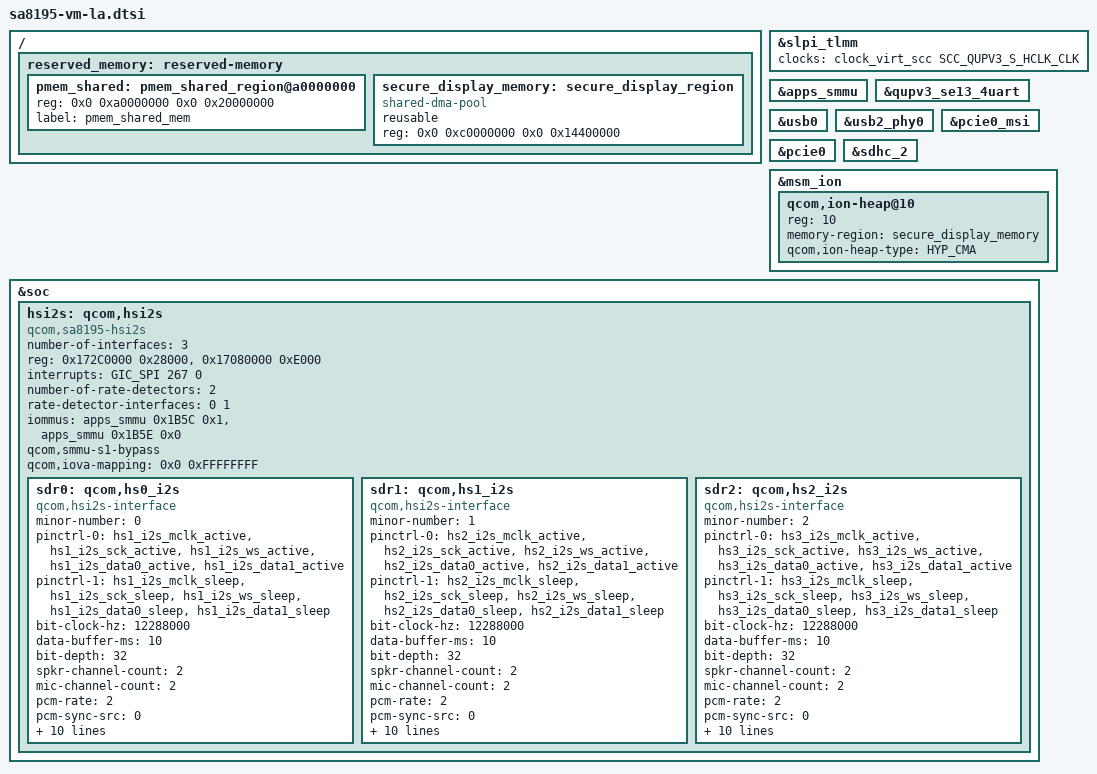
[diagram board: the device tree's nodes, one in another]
/* Copyright (c) 2019-2020, The Linux Foundation. All rights reserved.
 *
 * This program is free software; you can redistribute it and/or modify
 * it under the terms of the GNU General Public License version 2 and
 * only version 2 as published by the Free Software Foundation.
 *
 * This program is distributed in the hope that it will be useful,
 * but WITHOUT ANY WARRANTY; without even the implied warranty of
 * MERCHANTABILITY or FITNESS FOR A PARTICULAR PURPOSE.  See the
 * GNU General Public License for more details.
 */

/ {
	reserved_memory: reserved-memory {

		pmem_shared: pmem_shared_region@a0000000 {
			reg = <0x0 0xa0000000 0x0 0x20000000>;
			label = "pmem_shared_mem";
		};

		secure_display_memory: secure_display_region {
			compatible = "shared-dma-pool";
			reusable;
			reg = <0x0 0xc0000000 0x0 0x14400000>;
		};
	};

};

&slpi_tlmm {
	clocks =  <&clock_virt_scc SCC_QUPV3_S_HCLK_CLK>;
	status = "ok";
};

&apps_smmu {
	status = "ok";
};

&qupv3_se13_4uart {
	status = "ok";
};

&usb0 {
	status = "ok";
};

&usb2_phy0 {
	status = "ok";
};

&pcie0_msi {
	status = "ok";
};

&pcie0 {
	status = "ok";
};

&sdhc_2 {
	status = "ok";
};

&msm_ion {
	qcom,ion-heap@10 {
		reg = <10>;
		memory-region = <&secure_display_memory>;
		qcom,ion-heap-type = "HYP_CMA";
	};
};

&soc {
	hsi2s: qcom,hsi2s {
		compatible = "qcom,sa8195-hsi2s", "qcom,hsi2s";
		number-of-interfaces = <3>;
		reg = <0x172C0000 0x28000>,
		      <0x17080000 0xE000>;
		reg-names = "lpa_if", "lpass_tcsr";
		interrupts = <GIC_SPI 267 0>;
		number-of-rate-detectors = <2>;
		rate-detector-interfaces = <0 1>;
		iommus = <&apps_smmu 0x1B5C 0x1>,
			 <&apps_smmu 0x1B5E 0x0>;
		qcom,smmu-s1-bypass;
		qcom,iova-mapping = <0x0 0xFFFFFFFF>;

		sdr0: qcom,hs0_i2s {
			compatible = "qcom,hsi2s-interface";
			minor-number = <0>;
			pinctrl-names = "default", "sleep";
			pinctrl-0 = <&hs1_i2s_mclk_active &hs1_i2s_sck_active
				     &hs1_i2s_ws_active &hs1_i2s_data0_active
				     &hs1_i2s_data1_active>;
			pinctrl-1 = <&hs1_i2s_mclk_sleep &hs1_i2s_sck_sleep
				     &hs1_i2s_ws_sleep &hs1_i2s_data0_sleep
				     &hs1_i2s_data1_sleep>;
			bit-clock-hz = <12288000>;
			data-buffer-ms = <10>;
			bit-depth = <32>;
			spkr-channel-count = <2>;
			mic-channel-count = <2>;
			pcm-rate = <2>;
			pcm-sync-src = <0>;
			aux-mode = <0>;
			rpcm-width = <1>;
			tpcm-width = <1>;
			enable-tdm = <1>;
			tdm-rate = <32>;
			tdm-rpcm-width = <16>;
			tdm-tpcm-width = <16>;
			tdm-sync-delay = <2>;
			tdm-inv-sync = <0>;
			pcm-lane-config = <1>;
		};

		sdr1: qcom,hs1_i2s {
			compatible = "qcom,hsi2s-interface";
			minor-number = <1>;
			pinctrl-names = "default", "sleep";
			pinctrl-0 = <&hs2_i2s_mclk_active &hs2_i2s_sck_active
				     &hs2_i2s_ws_active &hs2_i2s_data0_active
				     &hs2_i2s_data1_active>;
			pinctrl-1 = <&hs2_i2s_mclk_sleep &hs2_i2s_sck_sleep
				     &hs2_i2s_ws_sleep &hs2_i2s_data0_sleep
				     &hs2_i2s_data1_sleep>;
			bit-clock-hz = <12288000>;
			data-buffer-ms = <10>;
			bit-depth = <32>;
			spkr-channel-count = <2>;
			mic-channel-count = <2>;
			pcm-rate = <2>;
			pcm-sync-src = <0>;
			aux-mode = <0>;
			rpcm-width = <1>;
			tpcm-width = <1>;
			enable-tdm = <1>;
			tdm-rate = <32>;
			tdm-rpcm-width = <16>;
			tdm-tpcm-width = <16>;
			tdm-sync-delay = <2>;
			tdm-inv-sync = <0>;
			pcm-lane-config = <1>;
		};

		sdr2: qcom,hs2_i2s {
			compatible = "qcom,hsi2s-interface";
			minor-number = <2>;
			pinctrl-names = "default", "sleep";
			pinctrl-0 = <&hs3_i2s_mclk_active &hs3_i2s_sck_active
				     &hs3_i2s_ws_active &hs3_i2s_data0_active
				     &hs3_i2s_data1_active>;
			pinctrl-1 = <&hs3_i2s_mclk_sleep &hs3_i2s_sck_sleep
				     &hs3_i2s_ws_sleep &hs3_i2s_data0_sleep
				     &hs3_i2s_data1_sleep>;
			bit-clock-hz = <12288000>;
			data-buffer-ms = <10>;
			bit-depth = <32>;
			spkr-channel-count = <2>;
			mic-channel-count = <2>;
			pcm-rate = <2>;
			pcm-sync-src = <0>;
			aux-mode = <0>;
			rpcm-width = <1>;
			tpcm-width = <1>;
			enable-tdm = <1>;
			tdm-rate = <32>;
			tdm-rpcm-width = <16>;
			tdm-tpcm-width = <16>;
			tdm-sync-delay = <2>;
			tdm-inv-sync = <0>;
			pcm-lane-config = <1>;
		};
	};
};
